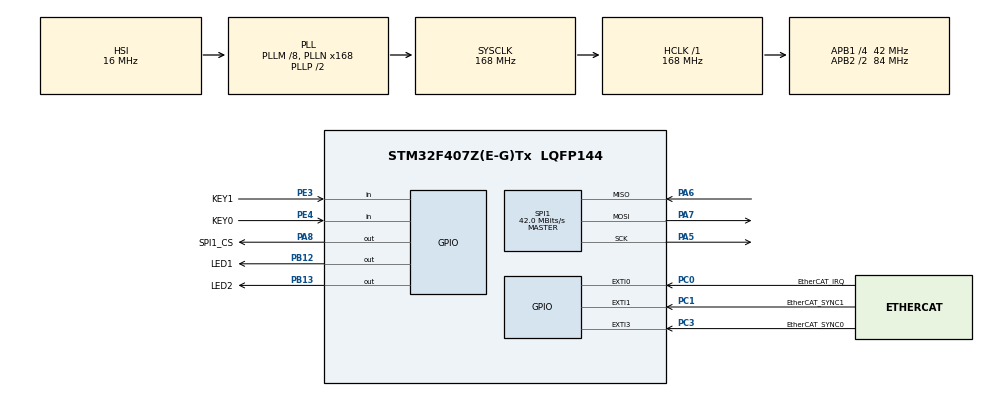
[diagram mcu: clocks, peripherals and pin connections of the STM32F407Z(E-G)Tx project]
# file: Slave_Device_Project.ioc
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Mcu.Family=STM32F4
Mcu.Name=STM32F407Z(E-G)Tx
Mcu.Package=LQFP144
NVIC.EXTI0_IRQn=true\:1\:0\:true\:false\:true\:true\:true\:true
NVIC.EXTI1_IRQn=true\:2\:0\:true\:false\:true\:true\:true\:true
NVIC.EXTI3_IRQn=true\:2\:0\:true\:false\:true\:true\:true\:true
NVIC.PriorityGroup=NVIC_PRIORITYGROUP_4
NVIC.TIM7_IRQn=true\:1\:0\:true\:false\:true\:true\:true\:true
PA13.Mode=Serial_Wire
PA13.Signal=SYS_JTMS-SWDIO
PA14.Mode=Serial_Wire
PA14.Signal=SYS_JTCK-SWCLK
PA5.Mode=Full_Duplex_Master
PA5.Signal=SPI1_SCK
PA6.Mode=Full_Duplex_Master
PA6.Signal=SPI1_MISO
PA7.Mode=Full_Duplex_Master
PA7.Signal=SPI1_MOSI
PA8.GPIO_Label=SPI1_CS
PA8.GPIO_PuPd=GPIO_PULLUP
PA8.GPIO_Speed=GPIO_SPEED_FREQ_VERY_HIGH
PA8.Signal=GPIO_Output
PB12.GPIO_Label=LED1
PB12.Signal=GPIO_Output
PB13.GPIO_Label=LED2
PB13.Signal=GPIO_Output
PC0.GPIO_Label=EtherCAT_IRQ
PC0.GPIO_ModeDefaultEXTI=GPIO_MODE_IT_FALLING
PC0.GPIO_PuPd=GPIO_PULLUP
PC0.Signal=GPXTI0
PC1.GPIO_Label=EtherCAT_SYNC1
PC1.GPIO_ModeDefaultEXTI=GPIO_MODE_IT_FALLING
PC1.GPIO_PuPd=GPIO_PULLUP
PC1.Signal=GPXTI1
PC3.GPIO_Label=EtherCAT_SYNC0
PC3.GPIO_ModeDefaultEXTI=GPIO_MODE_IT_FALLING
PC3.GPIO_PuPd=GPIO_PULLUP
PC3.Signal=GPXTI3
PE3.GPIO_Label=KEY1
PE3.Signal=GPIO_Input
PE4.GPIO_Label=KEY0
PE4.Signal=GPIO_Input
PH0-OSC_IN.Mode=HSE-External-Oscillator
PH0-OSC_IN.Signal=RCC_OSC_IN
PH1-OSC_OUT.Mode=HSE-External-Oscillator
PH1-OSC_OUT.Signal=RCC_OSC_OUT
ProjectManager.HeapSize=0x200
ProjectManager.StackSize=0x400
ProjectManager.TargetToolchain=MDK-ARM V5.32
RCC.48MHZClocksFreq_Value=84000000
RCC.AHBFreq_Value=168000000
RCC.APB1CLKDivider=RCC_HCLK_DIV4
RCC.APB1Freq_Value=42000000
RCC.APB1TimFreq_Value=84000000
RCC.APB2CLKDivider=RCC_HCLK_DIV2
RCC.APB2Freq_Value=84000000
RCC.APB2TimFreq_Value=168000000
RCC.CortexFreq_Value=168000000
RCC.HCLKFreq_Value=168000000
RCC.HSE_VALUE=8000000
RCC.HSI_VALUE=16000000
RCC.LSE_VALUE=32768
RCC.PLLM=8
RCC.PLLN=168
RCC.SYSCLKFreq_VALUE=168000000
RCC.SYSCLKSource=RCC_SYSCLKSOURCE_PLLCLK
RCC.VCOOutputFreq_Value=336000000
SPI1.CalculateBaudRate=42.0 MBits/s
SPI1.Direction=SPI_DIRECTION_2LINES
SPI1.Mode=SPI_MODE_MASTER
SPI1.VirtualType=VM_MASTER
TIM7.Period=2000-1
TIM7.Prescaler=42-1
VP_TIM7_VS_ClockSourceINT.Mode=Enable_Timer
board=custom

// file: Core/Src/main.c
/* USER CODE BEGIN Header */
/**
  ******************************************************************************
  * @file           : main.c
  * @brief          : Main program body
  ******************************************************************************
  * @attention
  *
  * Copyright (c) 2026 STMicroelectronics.
  * All rights reserved.
  *
  * This software is licensed under terms that can be found in the LICENSE file
  * in the root directory of this software component.
  * If no LICENSE file comes with this software, it is provided AS-IS.
  *
  ******************************************************************************
  */
/* USER CODE END Header */
#include "main.h"
#include "spi.h"
#include "tim.h"
#include "gpio.h"

/* USER CODE BEGIN Includes */
#include "applInterface.h"
/* USER CODE END Includes */

void SystemClock_Config(void);

int main(void)
{

  /* MCU Configuration--------------------------------------------------------*/

  /* Reset of all peripherals, Initializes the Flash interface and the Systick. */
  HAL_Init();

  /* Configure the system clock */
  SystemClock_Config();

  /* Initialize all configured peripherals */
  MX_GPIO_Init();
  MX_SPI1_Init();
  MX_TIM7_Init();
  /* USER CODE BEGIN 2 */
	HW_Init();
	MainInit();
  /* USER CODE END 2 */

  /* Infinite loop */
  while (1)
  {

    /* USER CODE BEGIN 3 */
		MainLoop();
  }
  /* USER CODE END 3 */
}

void SystemClock_Config(void)
{
  RCC_OscInitTypeDef RCC_OscInitStruct = {0};
  RCC_ClkInitTypeDef RCC_ClkInitStruct = {0};

  /** Configure the main internal regulator output voltage
  */
  __HAL_RCC_PWR_CLK_ENABLE();
  __HAL_PWR_VOLTAGESCALING_CONFIG(PWR_REGULATOR_VOLTAGE_SCALE1);

  /** Initializes the RCC Oscillators according to the specified parameters
  * in the RCC_OscInitTypeDef structure.
  */
  RCC_OscInitStruct.OscillatorType = RCC_OSCILLATORTYPE_HSI;
  RCC_OscInitStruct.HSIState = RCC_HSI_ON;
  RCC_OscInitStruct.HSICalibrationValue = RCC_HSICALIBRATION_DEFAULT;
  RCC_OscInitStruct.PLL.PLLState = RCC_PLL_ON;
  RCC_OscInitStruct.PLL.PLLSource = RCC_PLLSOURCE_HSI;
  RCC_OscInitStruct.PLL.PLLM = 8;
  RCC_OscInitStruct.PLL.PLLN = 168;
  RCC_OscInitStruct.PLL.PLLP = RCC_PLLP_DIV2;
  RCC_OscInitStruct.PLL.PLLQ = 4;
  if (HAL_RCC_OscConfig(&RCC_OscInitStruct) != HAL_OK)
  {
    Error_Handler();
  }

  /** Initializes the CPU, AHB and APB buses clocks
  */
  RCC_ClkInitStruct.ClockType = RCC_CLOCKTYPE_HCLK|RCC_CLOCKTYPE_SYSCLK
                              |RCC_CLOCKTYPE_PCLK1|RCC_CLOCKTYPE_PCLK2;
  RCC_ClkInitStruct.SYSCLKSource = RCC_SYSCLKSOURCE_PLLCLK;
  RCC_ClkInitStruct.AHBCLKDivider = RCC_SYSCLK_DIV1;
  RCC_ClkInitStruct.APB1CLKDivider = RCC_HCLK_DIV4;
  RCC_ClkInitStruct.APB2CLKDivider = RCC_HCLK_DIV2;

  if (HAL_RCC_ClockConfig(&RCC_ClkInitStruct, FLASH_LATENCY_5) != HAL_OK)
  {
    Error_Handler();
  }
}

void Error_Handler(void)
{
  __disable_irq();
  while (1)
  {
  }
}
